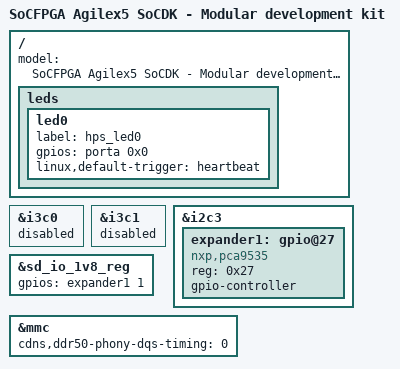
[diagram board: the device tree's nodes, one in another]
// SPDX-License-Identifier:     GPL-2.0
/*
 * Copyright (C) 2025, Altera Corporation
 */
#include "socfpga_agilex5_socdk.dts"

/ {
	model = "SoCFPGA Agilex5 SoCDK - Modular development kit";

	leds {
		led0 {
			label = "hps_led0";
			gpios = <&porta 0x0 GPIO_ACTIVE_HIGH>;
			linux,default-trigger = "heartbeat";
		};
	};
};

&i3c0 {
	status = "disabled";
};

&i3c1 {
	status = "disabled";
};

&i2c3 {
	status = "okay";

	expander1: gpio@27 {
		compatible = "nxp,pca9535";
		reg = <0x27>;			/* SoM expander address */
		gpio-controller;
		#gpio-cells = <2>;
	};
};

&sd_io_1v8_reg {
	gpios = <&expander1 1 GPIO_ACTIVE_HIGH>;
};

&mmc {
	/*
	 * The modular SoM's longer SD path offsets the returning DDR50 data from
	 * the fabricated phony strobe, collapsing one DDR beat onto both halves.
	 * Override the phony DQS assertion timing (default REBAR_PULSE_CYCLES-1 = 1)
	 * to 0 to re-centre the strobe so both beats are demuxed correctly.
	 */
	cdns,ddr50-phony-dqs-timing = <0>;
};
